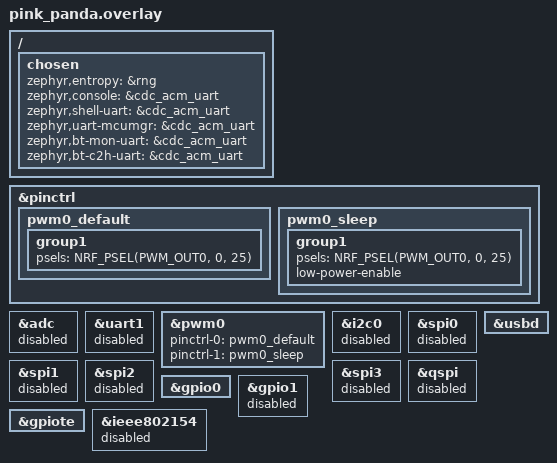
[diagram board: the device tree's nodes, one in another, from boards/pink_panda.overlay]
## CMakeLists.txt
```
cmake_minimum_required(VERSION 3.20.0)
list(APPEND BOARD_ROOT ${CMAKE_CURRENT_SOURCE_DIR})
find_package(Zephyr REQUIRED HINTS $ENV{ZEPHYR_BASE})

execute_process(COMMAND git describe
                WORKING_DIRECTORY ${CMAKE_CURRENT_SOURCE_DIR}
                OUTPUT_VARIABLE GIT_DESCRIBE
                ERROR_QUIET)
string(STRIP "${GIT_DESCRIBE}" GIT_DESCRIBE)
STRING(REGEX MATCH "[0-9]+\\.[0-9]+\\.[0-9]+"
       VERSION "${GIT_DESCRIBE}")

project(app LANGUAGES C VERSION ${VERSION})


configure_file(app_version.h.in ${CMAKE_BINARY_DIR}/app/include/app_version.h)
zephyr_include_directories(
    ${CMAKE_BINARY_DIR}/app/include
)
target_include_directories(app PRIVATE ${CMAKE_BINARY_DIR}/app/include src)

target_sources(app PRIVATE
        src/main.c)
```

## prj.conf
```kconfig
CONFIG_PM_DEVICE=y
CONFIG_LOG=y
CONFIG_HEAP_MEM_POOL_SIZE=2048
CONFIG_BOARD_SERIAL_BACKEND_CDC_ACM=y
CONFIG_PWM=y
CONFIG_PWM_SHELL=y
# CONFIG_LOG_RUNTIME_FILTERING is not set
CONFIG_LOG_BACKEND_UART=y
CONFIG_SHELL=y
```

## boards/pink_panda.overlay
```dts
/ {
	/*
	* In some default configurations within the nRF Connect SDK,
	* e.g. on nRF52840, the chosen zephyr,entropy node is &cryptocell.
	* This devicetree overlay ensures that default is overridden wherever it
	* is set, as this application uses the RNG node for entropy exclusively.
	*/
	chosen {
		zephyr,entropy = &rng;
		zephyr,console = &cdc_acm_uart;
		zephyr,shell-uart = &cdc_acm_uart;
		zephyr,uart-mcumgr = &cdc_acm_uart;
		zephyr,bt-mon-uart = &cdc_acm_uart;
		zephyr,bt-c2h-uart = &cdc_acm_uart;
	};
};
&pinctrl {
	pwm0_default: pwm0_default {
		group1 {
			psels = <NRF_PSEL(PWM_OUT0, 0, 25)>;
		};
	};

	pwm0_sleep: pwm0_sleep {
		group1 {
			psels = <NRF_PSEL(PWM_OUT0, 0, 25)>;
			low-power-enable;
		};
	};
};
&adc {
	status = "disabled";
};
&uart1 {
	status = "disabled";
};
&pwm0 {
	status = "okay";
	pinctrl-0 = <&pwm0_default>;
	pinctrl-1 = <&pwm0_sleep>;
	pinctrl-names = "default", "sleep";
};
&i2c0 {
	status = "disabled";
};
&spi0 {
	status = "disabled";
};
&spi1 {
	status = "disabled";
};
&spi2 {
	status = "disabled";
};
&spi3 {
	status = "disabled";
};
&qspi {
	status = "disabled";
};
&usbd {
	status = "okay";
};
&gpio0 {
	status = "okay";
};
&gpio1 {
	status = "disabled";
};
&gpiote {
    status = "okay";
};
&ieee802154 {
	status = "disabled";
};
```

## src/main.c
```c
#include <zephyr/drivers/gpio.h>
#include <zephyr/kernel.h>
#include <zephyr/pm/device.h>

#include <zephyr/logging/log.h>
LOG_MODULE_REGISTER(main, LOG_LEVEL_DBG);

#include <app_version.h>


int main(void)
{
	LOG_INF("🚀 MAIN START (%s) 🚀", APP_VERSION_FULL);
	return 0;
}
```
